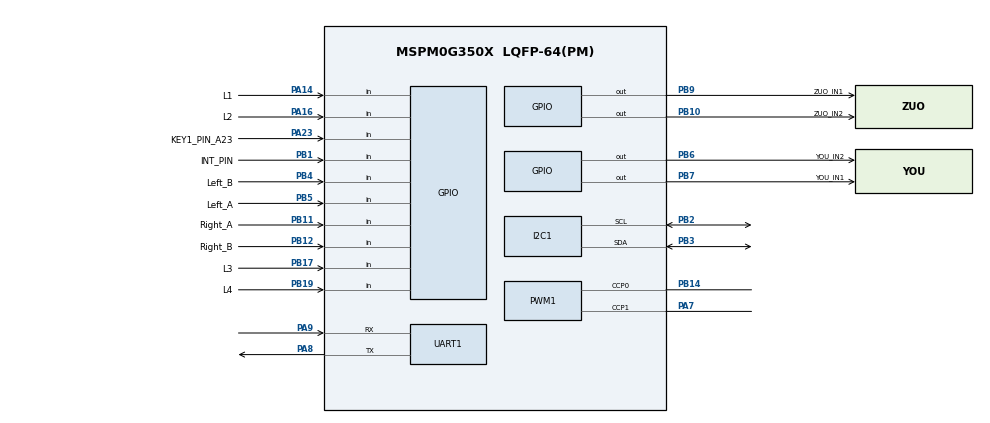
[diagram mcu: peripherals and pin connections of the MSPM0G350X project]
/**
 * @cliArgs --device "MSPM0G350X" --part "Default" --package "LQFP-64(PM)" --product "mspm0_sdk@2.04.00.06"
 * @versions {"tool":"1.23.1+4034"}
 */

/**
 * Import the modules used in this configuration.
 */
const Board   = scripting.addModule("/ti/driverlib/Board");
const GPIO    = scripting.addModule("/ti/driverlib/GPIO", {}, false);
const GPIO1   = GPIO.addInstance();
const GPIO2   = GPIO.addInstance();
const GPIO3   = GPIO.addInstance();
const GPIO4   = GPIO.addInstance();
const GPIO5   = GPIO.addInstance();
const GPIO6   = GPIO.addInstance();
const I2C     = scripting.addModule("/ti/driverlib/I2C", {}, false);
const I2C1    = I2C.addInstance();
const PWM     = scripting.addModule("/ti/driverlib/PWM", {}, false);
const PWM1    = PWM.addInstance();
const SYSCTL  = scripting.addModule("/ti/driverlib/SYSCTL");
const SYSTICK = scripting.addModule("/ti/driverlib/SYSTICK");
const TIMER   = scripting.addModule("/ti/driverlib/TIMER", {}, false);
const TIMER1  = TIMER.addInstance();
const UART    = scripting.addModule("/ti/driverlib/UART", {}, false);
const UART1   = UART.addInstance();

/**
 * Write custom configuration values to the imported modules.
 */
const divider7       = system.clockTree["PLL_PDIV"];
divider7.divideValue = 2;

const gate7  = system.clockTree["MFCLKGATE"];
gate7.enable = true;

const gate8  = system.clockTree["MFPCLKGATE"];
gate8.enable = true;

const multiplier2         = system.clockTree["PLL_QDIV"];
multiplier2.multiplyValue = 5;


GPIO1.$name                         = "OLED";
GPIO1.port                          = "PORTA";
GPIO1.associatedPins.create(2);
GPIO1.associatedPins[0].ioStructure = "OD";
GPIO1.associatedPins[0].assignedPin = "1";
GPIO1.associatedPins[0].$name       = "SCL1";
GPIO1.associatedPins[1].ioStructure = "OD";
GPIO1.associatedPins[1].assignedPin = "0";
GPIO1.associatedPins[1].$name       = "SDA1";

GPIO2.$name                          = "TB6612";
GPIO2.port                           = "PORTB";
GPIO2.associatedPins.create(4);
GPIO2.associatedPins[0].$name        = "ZUO_IN1";
GPIO2.associatedPins[0].initialValue = "SET";
GPIO2.associatedPins[0].assignedPin  = "9";
GPIO2.associatedPins[0].pin.$assign  = "PB9";
GPIO2.associatedPins[1].$name        = "ZUO_IN2";
GPIO2.associatedPins[1].initialValue = "SET";
GPIO2.associatedPins[1].assignedPin  = "10";
GPIO2.associatedPins[1].pin.$assign  = "PB10";
GPIO2.associatedPins[2].$name        = "YOU_IN1";
GPIO2.associatedPins[2].initialValue = "SET";
GPIO2.associatedPins[2].assignedPin  = "7";
GPIO2.associatedPins[2].pin.$assign  = "PB7";
GPIO2.associatedPins[3].$name        = "YOU_IN2";
GPIO2.associatedPins[3].initialValue = "SET";
GPIO2.associatedPins[3].assignedPin  = "6";
GPIO2.associatedPins[3].pin.$assign  = "PB6";

GPIO3.$name                         = "ENCODER";
GPIO3.port                          = "PORTB";
GPIO3.associatedPins.create(4);
GPIO3.associatedPins[0].$name       = "Right_B";
GPIO3.associatedPins[0].direction   = "INPUT";
GPIO3.associatedPins[0].assignedPin = "12";
GPIO3.associatedPins[0].interruptEn = true;
GPIO3.associatedPins[0].polarity    = "RISE";
GPIO3.associatedPins[0].pin.$assign = "PB12";
GPIO3.associatedPins[1].$name       = "Right_A";
GPIO3.associatedPins[1].direction   = "INPUT";
GPIO3.associatedPins[1].assignedPin = "11";
GPIO3.associatedPins[1].interruptEn = true;
GPIO3.associatedPins[1].polarity    = "FALL";
GPIO3.associatedPins[1].pin.$assign = "PB11";
GPIO3.associatedPins[2].$name       = "Left_B";
GPIO3.associatedPins[2].direction   = "INPUT";
GPIO3.associatedPins[2].assignedPin = "4";
GPIO3.associatedPins[2].interruptEn = true;
GPIO3.associatedPins[2].polarity    = "FALL";
GPIO3.associatedPins[2].pin.$assign = "PB4";
GPIO3.associatedPins[3].$name       = "Left_A";
GPIO3.associatedPins[3].direction   = "INPUT";
GPIO3.associatedPins[3].assignedPin = "5";
GPIO3.associatedPins[3].interruptEn = true;
GPIO3.associatedPins[3].polarity    = "RISE";
GPIO3.associatedPins[3].pin.$assign = "PB5";

GPIO4.$name                          = "GPIO_XUNJI";
GPIO4.associatedPins.create(8);
GPIO4.associatedPins[0].$name        = "L3";
GPIO4.associatedPins[0].direction    = "INPUT";
GPIO4.associatedPins[0].assignedPort = "PORTB";
GPIO4.associatedPins[0].assignedPin  = "17";
GPIO4.associatedPins[0].pin.$assign  = "PB17";
GPIO4.associatedPins[1].$name        = "L2";
GPIO4.associatedPins[1].direction    = "INPUT";
GPIO4.associatedPins[1].assignedPort = "PORTA";
GPIO4.associatedPins[1].assignedPin  = "16";
GPIO4.associatedPins[1].pin.$assign  = "PA16";
GPIO4.associatedPins[2].$name        = "L1";
GPIO4.associatedPins[2].direction    = "INPUT";
GPIO4.associatedPins[2].assignedPort = "PORTA";
GPIO4.associatedPins[2].assignedPin  = "14";
GPIO4.associatedPins[2].pin.$assign  = "PA14";
GPIO4.associatedPins[3].direction    = "INPUT";
GPIO4.associatedPins[3].assignedPort = "PORTB";
GPIO4.associatedPins[3].assignedPin  = "20";
GPIO4.associatedPins[3].$name        = "R1";
GPIO4.associatedPins[4].direction    = "INPUT";
GPIO4.associatedPins[4].assignedPort = "PORTB";
GPIO4.associatedPins[4].assignedPin  = "25";
GPIO4.associatedPins[4].$name        = "R2";
GPIO4.associatedPins[5].direction    = "INPUT";
GPIO4.associatedPins[5].assignedPort = "PORTA";
GPIO4.associatedPins[5].assignedPin  = "25";
GPIO4.associatedPins[5].$name        = "R3";
GPIO4.associatedPins[6].direction    = "INPUT";
GPIO4.associatedPins[6].assignedPort = "PORTA";
GPIO4.associatedPins[6].assignedPin  = "27";
GPIO4.associatedPins[6].$name        = "R4";
GPIO4.associatedPins[7].$name        = "L4";
GPIO4.associatedPins[7].direction    = "INPUT";
GPIO4.associatedPins[7].assignedPort = "PORTB";
GPIO4.associatedPins[7].assignedPin  = "19";
GPIO4.associatedPins[7].pin.$assign  = "PB19";

GPIO5.$name                              = "KEY";
GPIO5.port                               = "PORTA";
GPIO5.associatedPins[0].$name            = "KEY1_PIN_A23";
GPIO5.associatedPins[0].direction        = "INPUT";
GPIO5.associatedPins[0].internalResistor = "PULL_UP";

GPIO6.$name                         = "MPU6050";
GPIO6.port                          = "PORTB";
GPIO6.associatedPins[0].$name       = "INT_PIN";
GPIO6.associatedPins[0].assignedPin = "1";
GPIO6.associatedPins[0].direction   = "INPUT";
GPIO6.associatedPins[0].interruptEn = true;
GPIO6.associatedPins[0].polarity    = "FALL";

I2C1.$name                           = "I2C_0";
I2C1.basicEnableController           = true;
I2C1.basicControllerStandardBusSpeed = "Standard";
I2C1.peripheral.$assign              = "I2C1";
I2C1.peripheral.sdaPin.$assign       = "PB3";
I2C1.peripheral.sclPin.$assign       = "PB2";
I2C1.sdaPinConfig.$name              = "ti_driverlib_gpio_GPIOPinGeneric2";
I2C1.sclPinConfig.$name              = "ti_driverlib_gpio_GPIOPinGeneric3";

PWM1.$name                              = "PWMAB";
PWM1.timerStartTimer                    = true;
PWM1.timerCount                         = 100;
PWM1.pwmMode                            = "EDGE_ALIGN_UP";
PWM1.peripheral.$assign                 = "TIMA0";
PWM1.peripheral.ccp0Pin.$assign         = "PB14";
PWM1.peripheral.ccp1Pin.$assign         = "PA7";
PWM1.PWM_CHANNEL_0.$name                = "ti_driverlib_pwm_PWMTimerCC0";
PWM1.PWM_CHANNEL_1.$name                = "ti_driverlib_pwm_PWMTimerCC1";
PWM1.ccp0PinConfig.direction            = scripting.forceWrite("OUTPUT");
PWM1.ccp0PinConfig.hideOutputInversion  = scripting.forceWrite(false);
PWM1.ccp0PinConfig.onlyInternalResistor = scripting.forceWrite(false);
PWM1.ccp0PinConfig.passedPeripheralType = scripting.forceWrite("Digital");
PWM1.ccp0PinConfig.$name                = "ti_driverlib_gpio_GPIOPinGeneric4";
PWM1.ccp1PinConfig.direction            = scripting.forceWrite("OUTPUT");
PWM1.ccp1PinConfig.hideOutputInversion  = scripting.forceWrite(false);
PWM1.ccp1PinConfig.onlyInternalResistor = scripting.forceWrite(false);
PWM1.ccp1PinConfig.passedPeripheralType = scripting.forceWrite("Digital");
PWM1.ccp1PinConfig.$name                = "ti_driverlib_gpio_GPIOPinGeneric5";

SYSCTL.forceDefaultClkConfig = true;
SYSCTL.clockTreeEn           = true;

SYSTICK.periodEnable    = true;
SYSTICK.systickEnable   = true;
SYSTICK.interruptEnable = true;
SYSTICK.period          = 32000;

TIMER1.$name              = "TIMER_A1_KONG_ZHI";
TIMER1.timerClkDiv        = 8;
TIMER1.timerClkPrescale   = 40;
TIMER1.timerMode          = "PERIODIC";
TIMER1.timerPeriod        = "0.005";
TIMER1.timerStartTimer    = true;
TIMER1.interrupts         = ["ZERO"];
TIMER1.peripheral.$assign = "TIMA1";

UART1.$name                            = "UART_1";
UART1.uartClkSrc                       = "MFCLK";
UART1.enabledInterrupts                = ["RX"];
UART1.targetBaudRate                   = 115200;
UART1.peripheral.$assign               = "UART1";
UART1.peripheral.rxPin.$assign         = "PA9";
UART1.peripheral.txPin.$assign         = "PA8";
UART1.txPinConfig.direction            = scripting.forceWrite("OUTPUT");
UART1.txPinConfig.hideOutputInversion  = scripting.forceWrite(false);
UART1.txPinConfig.onlyInternalResistor = scripting.forceWrite(false);
UART1.txPinConfig.passedPeripheralType = scripting.forceWrite("Digital");
UART1.txPinConfig.$name                = "ti_driverlib_gpio_GPIOPinGeneric0";
UART1.rxPinConfig.hideOutputInversion  = scripting.forceWrite(false);
UART1.rxPinConfig.onlyInternalResistor = scripting.forceWrite(false);
UART1.rxPinConfig.passedPeripheralType = scripting.forceWrite("Digital");
UART1.rxPinConfig.$name                = "ti_driverlib_gpio_GPIOPinGeneric1";

/**
 * Pinmux solution for unlocked pins/peripherals. This ensures that minor changes to the automatic solver in a future
 * version of the tool will not impact the pinmux you originally saw.  These lines can be completely deleted in order to
 * re-solve from scratch.
 */
Board.peripheral.$suggestSolution            = "DEBUGSS";
Board.peripheral.swclkPin.$suggestSolution   = "PA20";
Board.peripheral.swdioPin.$suggestSolution   = "PA19";
GPIO1.associatedPins[0].pin.$suggestSolution = "PA1";
GPIO1.associatedPins[1].pin.$suggestSolution = "PA0";
GPIO4.associatedPins[3].pin.$suggestSolution = "PB20";
GPIO4.associatedPins[4].pin.$suggestSolution = "PB25";
GPIO4.associatedPins[5].pin.$suggestSolution = "PA25";
GPIO4.associatedPins[6].pin.$suggestSolution = "PA27";
GPIO5.associatedPins[0].assignedPin = "23";
GPIO5.associatedPins[0].pin.$assign = "PA23";
GPIO6.associatedPins[0].pin.$assign = "PB1";
